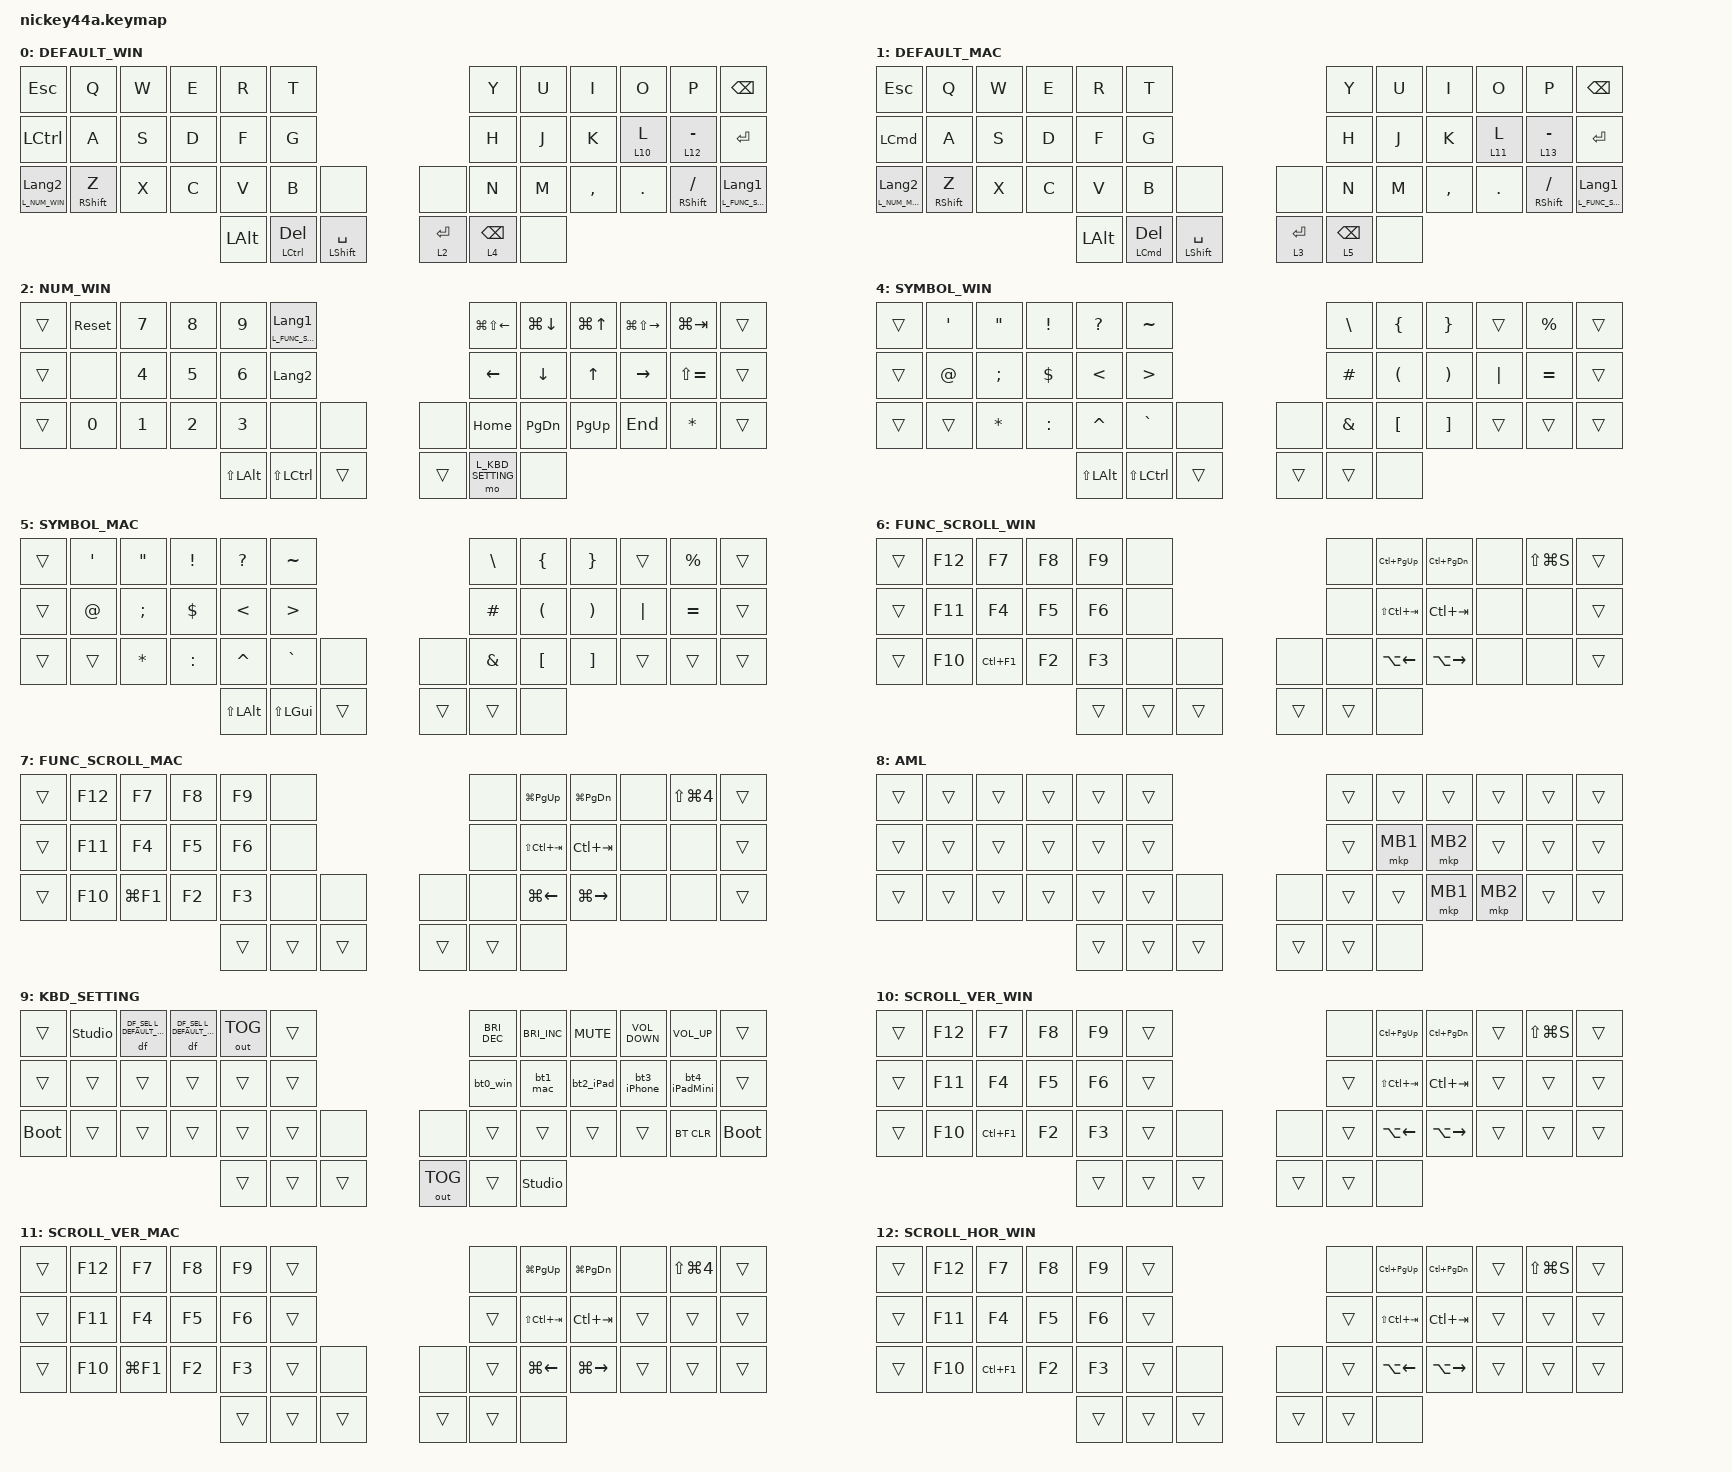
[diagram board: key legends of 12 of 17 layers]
#include <behaviors.dtsi>
#include <behaviors/default_layer.dtsi>
#include <dt-bindings/zmk_behavior_default_layer/default_layer.h>
#include <dt-bindings/zmk/bt.h>
#include <dt-bindings/zmk/keys.h>
#include <dt-bindings/zmk/outputs.h>
#include <dt-bindings/zmk/pointing.h>
#include <input/processors.dtsi>
#include "nickey_layers.h"

&mmv {
    delay-ms = <20>;
    time-to-max-speed-ms = <300>;
    acceleration-exponent = <2>;
};

&msc {
    delay-ms = <0>;
    time-to-max-speed-ms = <500>;
    acceleration-exponent = <2>;
};

#if NICKEY_AUTO_MOUSE_LAYER
&mkp_input_listener { input-processors = <&zip_temp_layer L_AML 250>; };
#endif

&mt {
    flavor = "balanced";
    tapping-term-ms = <180>;
    quick-tap-ms = <180>;
};

&lt {
    tapping-term-ms = <180>;
    quick-tap-ms = <180>;
};

&sl { release-after-ms = <30000>; };

&zip_temp_layer {
    excluded-positions = <19 20 39 40>; // J, K, Delete, Space
    require-prior-idle-ms = <300>;
};

/ {
    combos {
        compatible = "zmk,combos";

        tab {
            bindings = <&kp TAB>;
            key-positions = <14 15>;
            timeout-ms = <80>;
        };

        shift_tab {
            bindings = <&kp LS(TAB)>;
            key-positions = <15 16>;
            timeout-ms = <80>;
        };

        Esc {
            bindings = <&kp ESCAPE>;
            key-positions = <1 2>;
            timeout-ms = <80>;
        };

        middle_click {
            bindings = <&mkp MB3>;
            key-positions = <19 20>;
        };

        caps_lock {
            bindings = <&kp CAPSLOCK>;
            key-positions = <13 14>;
        };

        middle_click_alt {
            bindings = <&mkp MB3>;
            key-positions = <34 35>;
        };
    };

    macros {
        bt0_win: bt0 {
            compatible = "zmk,behavior-macro";
            #binding-cells = <0>;
            bindings =
                <&bt BT_SEL 0 &bt BT_DISC 1 &bt BT_DISC 2 &bt BT_DISC 3 &bt BT_DISC 4>,
                <&macro_wait_time 200>,
                <&df DF_SEL L_DEFAULT_WIN>;

            display-name = "BT0";
        };

        bt1_mac: bt1 {
            compatible = "zmk,behavior-macro";
            #binding-cells = <0>;
            bindings =
                <&bt BT_SEL 1 &bt BT_DISC 0 &bt BT_DISC 2 &bt BT_DISC 3 &bt BT_DISC 4>,
                <&macro_wait_time 200>,
                <&df DF_SEL L_DEFAULT_MAC>;

            display-name = "BT1";
        };

        bt2_iPad: bt2_iPad {
            compatible = "zmk,behavior-macro";
            #binding-cells = <0>;
            bindings =
                <&bt BT_SEL 2 &bt BT_DISC 0 &bt BT_DISC 1 &bt BT_DISC 3 &bt BT_DISC 4>,
                <&macro_wait_time 200>,
                <&df DF_SEL L_DEFAULT_MAC>;

            display-name = "BT2_IPAD";
        };

        bt3_iPhone: bt3_iPhone {
            compatible = "zmk,behavior-macro";
            #binding-cells = <0>;
            bindings =
                <&bt BT_SEL 3 &bt BT_DISC 0 &bt BT_DISC 1 &bt BT_DISC 2 &bt BT_DISC 4>,
                <&macro_wait_time 200>,
                <&df DF_SEL L_DEFAULT_MAC>;

            display-name = "BT3_IPHONE";
        };

        bt4_iPadMini: bt4_iPadMini {
            compatible = "zmk,behavior-macro";
            #binding-cells = <0>;
            bindings =
                <&bt BT_SEL 4 &bt BT_DISC 0 &bt BT_DISC 1 &bt BT_DISC 2 &bt BT_DISC 3>,
                <&macro_wait_time 200>,
                <&df DF_SEL L_DEFAULT_MAC>;

            display-name = "BT4_IPADMINI";
        };
    };

    keymap {
        compatible = "zmk,keymap";

        default_win {
            display-name = "DEFAULT_WIN";
            bindings = <
            &kp ESCAPE                &kp Q         &kp W  &kp E  &kp R         &kp T                                                   &kp Y            &kp U  &kp I      &kp O       &kp P             &kp BACKSPACE
            &kp LEFT_CONTROL          &kp A         &kp S  &kp D  &kp F         &kp G                                                   &kp H            &kp J  &kp K      &lt 10 L    &lt 12 MINUS      &kp ENTER
            &lt L_NUM_WIN LANGUAGE_2  &mt RSHIFT Z  &kp X  &kp C  &kp V         &kp B             &none                    &none        &kp N            &kp M  &kp COMMA  &kp PERIOD  &mt RSHIFT SLASH  &lt L_FUNC_SCROLL_WIN LANGUAGE_1
                                               &kp LEFT_ALT  &mt LCTRL DELETE  &mt LEFT_SHIFT SPACE     &lt 2 ENTER  &lt 4 BACKSPACE  &none
            >;
        };

        default_mac {
            display-name = "DEFAULT_MAC";
            bindings = <
            &kp ESCAPE                &kp Q         &kp W  &kp E  &kp R         &kp T                                                          &kp Y            &kp U  &kp I      &kp O       &kp P             &kp BACKSPACE
            &kp LEFT_COMMAND          &kp A         &kp S  &kp D  &kp F         &kp G                                                          &kp H            &kp J  &kp K      &lt 11 L    &lt 13 MINUS      &kp ENTER
            &lt L_NUM_MAC LANGUAGE_2  &mt RSHIFT Z  &kp X  &kp C  &kp V         &kp B                    &none                    &none        &kp N            &kp M  &kp COMMA  &kp PERIOD  &mt RSHIFT SLASH  &lt L_FUNC_SCROLL_MAC LANGUAGE_1
                                               &kp LEFT_ALT  &mt LEFT_COMMAND DELETE  &mt LEFT_SHIFT SPACE     &lt 3 ENTER  &lt 5 BACKSPACE  &none
            >;
        };

        num_win {
            display-name = "NUM_WIN";
            bindings = <
            &trans  &sys_reset    &kp NUMBER_7  &kp NUMBER_8  &kp NUMBER_9      &lt L_FUNC_SCROLL_WIN LANGUAGE_1                     &kp LG(LS(LEFT))   &kp LG(DOWN)   &kp LG(UP_ARROW)  &kp LG(LS(RIGHT))  &kp LG(TAB)    &trans
            &trans  &none         &kp NUMBER_4  &kp NUMBER_5  &kp NUMBER_6      &kp LANGUAGE_2                                       &kp LEFT           &kp DOWN       &kp UP            &kp RIGHT          &kp LS(EQUAL)  &trans
            &trans  &kp NUMBER_0  &kp NUMBER_1  &kp NUMBER_2  &kp NUMBER_3      &none                             &none      &none   &kp HOME           &kp PAGE_DOWN  &kp PAGE_UP       &kp END            &kp ASTERISK   &trans
                                                             &kp LS(LEFT_ALT)  &kp LS(LEFT_CONTROL)              &trans     &trans  &mo L_KBD_SETTING  &none
            >;
        };

        num_mac {
            display-name = "NUM_MAC";
            bindings = <
            &trans  &sys_reset  &kp N7  &kp N8  &kp N9            &lt L_FUNC_SCROLL_MAC LANGUAGE_1                     &kp LC(LA(LG(LEFT)))  &kp LC(DOWN)  &kp LC(UP_ARROW)  &kp LC(LA(LG(RIGHT)))  &kp LC(LA(ENTER))  &trans
            &trans  &none       &kp N4  &kp N5  &kp N6            &kp LANGUAGE_2                                       &kp LEFT              &kp DOWN      &kp UP            &kp RIGHT              &kp LS(EQUAL)      &trans
            &trans  &kp N0      &kp N1  &kp N2  &kp N3            &none                             &none      &none   &kp LG(LEFT)          &kp LG(DOWN)  &kp LG(UP)        &kp LG(RIGHT)          &kp ASTERISK       &trans
                                               &kp LS(LEFT_ALT)  &kp LS(LEFT_GUI)                  &trans     &trans  &mo L_KBD_SETTING     &none
            >;
        };

        symbol_win {
            display-name = "SYMBOL_WIN";
            bindings = <
            &trans  &kp SQT      &kp DOUBLE_QUOTES  &kp EXCLAMATION  &kp QUESTION      &kp TILDE                            &kp BACKSLASH  &kp LEFT_BRACE        &kp RIGHT_BRACE        &trans    &kp PERCENT  &trans
            &trans  &kp AT_SIGN  &kp SEMICOLON      &kp DOLLAR       &kp LESS_THAN     &kp GREATER_THAN                     &kp HASH       &kp LEFT_PARENTHESIS  &kp RIGHT_PARENTHESIS  &kp PIPE  &kp EQUAL    &trans
            &trans  &trans       &kp ASTERISK       &kp COLON        &kp CARET         &kp GRAVE         &none      &none   &kp AMPERSAND  &kp LEFT_BRACKET      &kp RIGHT_BRACKET      &trans    &trans       &trans
                                                                    &kp LS(LEFT_ALT)  &kp LS(LCTRL)     &trans     &trans  &trans         &none
            >;
        };

        symbol_mac {
            display-name = "SYMBOL_MAC";
            bindings = <
            &trans  &kp SQT      &kp DOUBLE_QUOTES  &kp EXCLAMATION  &kp QUESTION      &kp TILDE                            &kp BACKSLASH  &kp LEFT_BRACE        &kp RIGHT_BRACE        &trans    &kp PERCENT  &trans
            &trans  &kp AT_SIGN  &kp SEMICOLON      &kp DOLLAR       &kp LESS_THAN     &kp GREATER_THAN                     &kp HASH       &kp LEFT_PARENTHESIS  &kp RIGHT_PARENTHESIS  &kp PIPE  &kp EQUAL    &trans
            &trans  &trans       &kp ASTERISK       &kp COLON        &kp CARET         &kp GRAVE         &none      &none   &kp AMPERSAND  &kp LEFT_BRACKET      &kp RIGHT_BRACKET      &trans    &trans       &trans
                                                                    &kp LS(LEFT_ALT)  &kp LS(LEFT_GUI)  &trans     &trans  &trans         &none
            >;
        };

        func_scroll_win {
            display-name = "FUNC_SCROLL_WIN";
            bindings = <
            &trans  &kp F12  &kp F7      &kp F8  &kp F9  &none                      &none   &kp LC(PAGE_UP)  &kp LC(PAGE_DOWN)  &none  &kp LS(LG(S))  &trans
            &trans  &kp F11  &kp F4      &kp F5  &kp F6  &none                      &none   &kp LS(LC(TAB))  &kp LC(TAB)        &none  &none          &trans
            &trans  &kp F10  &kp LC(F1)  &kp F2  &kp F3  &none   &none      &none   &none   &kp LA(LEFT)     &kp LA(RIGHT)      &none  &none          &trans
                                                &trans  &trans  &trans     &trans  &trans  &none
            >;
        };

        func_scroll_mac {
            display-name = "FUNC_SCROLL_MAC";
            bindings = <
            &trans  &kp F12  &kp F7      &kp F8  &kp F9  &none                      &none   &kp LG(PAGE_UP)  &kp LG(PAGE_DOWN)  &none  &kp LS(LG(NUMBER_4))  &trans
            &trans  &kp F11  &kp F4      &kp F5  &kp F6  &none                      &none   &kp LS(LC(TAB))  &kp LC(TAB)        &none  &none                 &trans
            &trans  &kp F10  &kp LG(F1)  &kp F2  &kp F3  &none   &none      &none   &none   &kp LG(LEFT)     &kp LG(RIGHT)      &none  &none                 &trans
                                                &trans  &trans  &trans     &trans  &trans  &none
            >;
        };

        aml {
            display-name = "AML";
            bindings = <
            &trans  &trans  &trans  &trans  &trans  &trans                     &trans  &trans    &trans    &trans    &trans  &trans
            &trans  &trans  &trans  &trans  &trans  &trans                     &trans  &mkp MB1  &mkp MB2  &trans    &trans  &trans
            &trans  &trans  &trans  &trans  &trans  &trans  &none      &none   &trans  &trans    &mkp MB1  &mkp MB2  &trans  &trans
                                           &trans  &trans  &trans     &trans  &trans  &none
            >;
        };

        kbd_setting {
            display-name = "KBD_SETTING";
            bindings = <
            &trans  &studio_unlock  &df DF_SEL L_DEFAULT_WIN  &df DF_SEL L_DEFAULT_MAC  &out OUT_TOG  &trans                           &kp C_BRIGHTNESS_DEC  &kp C_BRIGHTNESS_INC  &kp K_MUTE  &kp C_VOLUME_DOWN  &kp C_VOLUME_UP  &trans
            &trans  &trans          &trans                    &trans                    &trans        &trans                           &bt0_win              &bt1_mac              &bt2_iPad   &bt3_iPhone        &bt4_iPadMini    &trans
            &bootloader  &trans          &trans                    &trans                    &trans        &trans  &none      &none         &trans                &trans                &trans      &trans             &bt BT_CLR       &bootloader
                                                                                       &trans        &trans  &trans     &out OUT_TOG  &trans                &studio_unlock
            >;
        };

        scroll_ver_win {
            display-name = "SCROLL_VER_WIN";
            bindings = <
            &trans  &kp F12  &kp F7      &kp F8  &kp F9  &trans                     &none   &kp LC(PAGE_UP)  &kp LC(PAGE_DOWN)  &trans  &kp LS(LG(S))  &trans
            &trans  &kp F11  &kp F4      &kp F5  &kp F6  &trans                     &trans  &kp LS(LC(TAB))  &kp LC(TAB)        &trans  &trans         &trans
            &trans  &kp F10  &kp LC(F1)  &kp F2  &kp F3  &trans  &none      &none   &trans  &kp LA(LEFT)     &kp LA(RIGHT)      &trans  &trans         &trans
                                                &trans  &trans  &trans     &trans  &trans  &none
            >;
        };

        scroll_ver_mac {
            display-name = "SCROLL_VER_MAC";
            bindings = <
            &trans  &kp F12  &kp F7      &kp F8  &kp F9  &trans                     &none   &kp LG(PAGE_UP)  &kp LG(PAGE_DOWN)  &none   &kp LS(LG(NUMBER_4))  &trans
            &trans  &kp F11  &kp F4      &kp F5  &kp F6  &trans                     &trans  &kp LS(LC(TAB))  &kp LC(TAB)        &trans  &trans                &trans
            &trans  &kp F10  &kp LG(F1)  &kp F2  &kp F3  &trans  &none      &none   &trans  &kp LG(LEFT)     &kp LG(RIGHT)      &trans  &trans                &trans
                                                &trans  &trans  &trans     &trans  &trans  &none
            >;
        };

        scroll_hor_win {
            display-name = "SCROLL_HOR_WIN";
            bindings = <
            &trans  &kp F12  &kp F7      &kp F8  &kp F9  &trans                     &none   &kp LC(PAGE_UP)  &kp LC(PAGE_DOWN)  &trans  &kp LS(LG(S))  &trans
            &trans  &kp F11  &kp F4      &kp F5  &kp F6  &trans                     &trans  &kp LS(LC(TAB))  &kp LC(TAB)        &trans  &trans         &trans
            &trans  &kp F10  &kp LC(F1)  &kp F2  &kp F3  &trans  &none      &none   &trans  &kp LA(LEFT)     &kp LA(RIGHT)      &trans  &trans         &trans
                                                &trans  &trans  &trans     &trans  &trans  &none
            >;
        };

        scroll_hor_mac {
            display-name = "SCROLL_HOR_MAC";
            bindings = <
            &trans  &kp F12  &kp F7      &kp F8  &kp F9  &trans                     &none   &kp LG(PAGE_UP)  &kp LG(PAGE_DOWN)  &none   &kp LS(LG(NUMBER_4))  &trans
            &trans  &kp F11  &kp F4      &kp F5  &kp F6  &trans                     &trans  &kp LS(LC(TAB))  &kp LC(TAB)        &trans  &trans                &trans
            &trans  &kp F10  &kp LG(F1)  &kp F2  &kp F3  &trans  &none      &none   &trans  &kp LG(LEFT)     &kp LG(RIGHT)      &trans  &trans                &trans
                                                &trans  &trans  &trans     &trans  &trans  &none
            >;
        };

        gesture_win {
            display-name = "GESTURE_WIN";
            bindings = <
            &trans  &trans  &trans  &trans  &trans  &trans                     &trans  &trans  &trans  &trans  &trans  &trans
            &trans  &trans  &trans  &trans  &trans  &trans                     &trans  &trans  &trans  &trans  &trans  &trans
            &trans  &trans  &trans  &trans  &trans  &trans  &none      &none   &trans  &trans  &trans  &trans  &trans  &trans
                                           &trans  &trans  &trans     &trans  &trans  &none
            >;
        };

        gesture_mac {
            display-name = "GESTURE_MAC";
            bindings = <
            &trans  &trans  &trans  &trans  &trans  &trans                     &trans  &trans  &trans  &trans  &trans  &trans
            &trans  &trans  &trans  &trans  &trans  &trans                     &trans  &trans  &trans  &trans  &trans  &trans
            &trans  &trans  &trans  &trans  &trans  &trans  &none      &none   &trans  &trans  &trans  &trans  &trans  &trans
                                           &trans  &trans  &trans     &trans  &trans  &none
            >;
        };

        win_scroll_dir {
            display-name = "WIN_SCROLL_DIR";
            bindings = <
            &trans  &trans  &trans  &trans  &trans  &trans                     &trans  &trans  &trans  &trans  &trans  &trans
            &trans  &trans  &trans  &trans  &trans  &trans                     &trans  &trans  &trans  &trans  &trans  &trans
            &trans  &trans  &trans  &trans  &trans  &trans  &none      &none   &trans  &trans  &trans  &trans  &trans  &trans
                                           &trans  &trans  &trans     &trans  &trans  &none
            >;
        };
    };

    conditional_layers {
        compatible = "zmk,conditional-layers";

        Gesture_win {
            if-layers = <L_SCROLL_VER_WIN L_SCROLL_HOR_WIN>;
            then-layer = <L_GESTURE_WIN>;
        };

        Gesture_mac {
            if-layers = <L_SCROLL_VER_MAC L_SCROLL_HOR_MAC>;
            then-layer = <L_GESTURE_MAC>;
        };
    };
};
